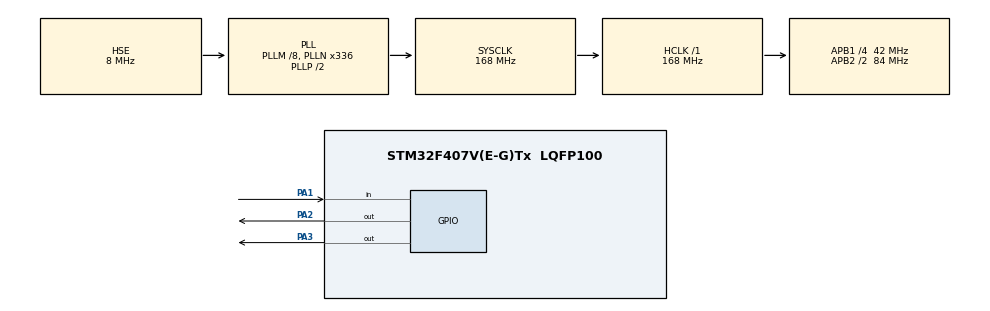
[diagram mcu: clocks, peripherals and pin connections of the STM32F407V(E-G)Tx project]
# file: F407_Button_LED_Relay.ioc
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Mcu.Family=STM32F4
Mcu.Name=STM32F407V(E-G)Tx
Mcu.Package=LQFP100
NVIC.PriorityGroup=NVIC_PRIORITYGROUP_4
PA1.GPIO_PuPd=GPIO_PULLUP
PA1.Signal=GPIO_Input
PA13.Mode=Trace_Asynchronous_SW
PA13.Signal=SYS_JTMS-SWDIO
PA14.Mode=Trace_Asynchronous_SW
PA14.Signal=SYS_JTCK-SWCLK
PA2.GPIO_ModeDefaultOutputPP=GPIO_MODE_OUTPUT_PP
PA2.GPIO_PuPd=GPIO_NOPULL
PA2.GPIO_Speed=GPIO_SPEED_FREQ_HIGH
PA2.PinState=GPIO_PIN_RESET
PA2.Signal=GPIO_Output
PA3.GPIO_ModeDefaultOutputPP=GPIO_MODE_OUTPUT_PP
PA3.GPIO_PuPd=GPIO_NOPULL
PA3.GPIO_Speed=GPIO_SPEED_FREQ_HIGH
PA3.PinState=GPIO_PIN_RESET
PA3.Signal=GPIO_Output
PB3.Mode=Trace_Asynchronous_SW
PB3.Signal=SYS_JTDO-SWO
PH0-OSC_IN.Mode=HSE-External-Oscillator
PH0-OSC_IN.Signal=RCC_OSC_IN
PH1-OSC_OUT.Mode=HSE-External-Oscillator
PH1-OSC_OUT.Signal=RCC_OSC_OUT
ProjectManager.HeapSize=0x200
ProjectManager.StackSize=0x400
ProjectManager.TargetToolchain=MDK-ARM V5.27
RCC.48MHZClocksFreq_Value=84000000
RCC.AHBFreq_Value=168000000
RCC.APB1CLKDivider=RCC_HCLK_DIV4
RCC.APB1Freq_Value=42000000
RCC.APB1TimFreq_Value=84000000
RCC.APB2CLKDivider=RCC_HCLK_DIV2
RCC.APB2Freq_Value=84000000
RCC.APB2TimFreq_Value=168000000
RCC.CortexFreq_Value=168000000
RCC.HCLKFreq_Value=168000000
RCC.HSE_VALUE=8000000
RCC.HSI_VALUE=16000000
RCC.LSE_VALUE=32768
RCC.PLLM=8
RCC.PLLN=336
RCC.PLLSourceVirtual=RCC_PLLSOURCE_HSE
RCC.SYSCLKFreq_VALUE=168000000
RCC.SYSCLKSource=RCC_SYSCLKSOURCE_PLLCLK
RCC.VCOOutputFreq_Value=336000000
board=custom

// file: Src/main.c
/* This code for STM32F407VG
Hardware setup:
PA1 -> GPIO_Input -> Pull up initialize,
    That means button is connected to GND,
		through RES10K to the PA0,1
PA2,3 -> GPIO_Output -> Output level (initial) low
			  								Mode - Output Push Pull
				  							No pull up/down
					  						Max. Output Speed - High
*/
#include "main.h"
#include "stdio.h"
void SystemClock_Config(void);
static void MX_GPIO_Init(void);
struct __FILE{
  int handle;
  /* Whatever you require here. If the only file you are using is */
  /* standard output using printf() for debugging, no file handling */
  /* is required. */
};
uint8_t count;
int main(void)
{
  HAL_Init();
  SystemClock_Config();
  MX_GPIO_Init();
  count = 0;
	while (1)
  {
		if(HAL_GPIO_ReadPin(GPIOA, GPIO_PIN_1) == 0)
		{
			count ++;
			if (count > 20)
				count = 0;
			HAL_Delay(200);																			//Bound effect avoidance
			while(HAL_GPIO_ReadPin(GPIOA, GPIO_PIN_1) == 0);		//Bound effect avoidance
			//HAL_Delay(200);																			//Bound effect avoidance
			HAL_GPIO_TogglePin(GPIOA, GPIO_PIN_2);
			HAL_GPIO_TogglePin(GPIOA, GPIO_PIN_3);
		}
  }
}

void SystemClock_Config(void)
{
  RCC_OscInitTypeDef RCC_OscInitStruct = {0};
  RCC_ClkInitTypeDef RCC_ClkInitStruct = {0};

  /** Configure the main internal regulator output voltage
  */
  __HAL_RCC_PWR_CLK_ENABLE();
  __HAL_PWR_VOLTAGESCALING_CONFIG(PWR_REGULATOR_VOLTAGE_SCALE1);
  /** Initializes the RCC Oscillators according to the specified parameters
  * in the RCC_OscInitTypeDef structure.
  */
  RCC_OscInitStruct.OscillatorType = RCC_OSCILLATORTYPE_HSE;
  RCC_OscInitStruct.HSEState = RCC_HSE_ON;
  RCC_OscInitStruct.PLL.PLLState = RCC_PLL_ON;
  RCC_OscInitStruct.PLL.PLLSource = RCC_PLLSOURCE_HSE;
  RCC_OscInitStruct.PLL.PLLM = 8;
  RCC_OscInitStruct.PLL.PLLN = 336;
  RCC_OscInitStruct.PLL.PLLP = RCC_PLLP_DIV2;
  RCC_OscInitStruct.PLL.PLLQ = 4;
  if (HAL_RCC_OscConfig(&RCC_OscInitStruct) != HAL_OK)
  {
    Error_Handler();
  }
  /** Initializes the CPU, AHB and APB buses clocks
  */
  RCC_ClkInitStruct.ClockType = RCC_CLOCKTYPE_HCLK|RCC_CLOCKTYPE_SYSCLK
                              |RCC_CLOCKTYPE_PCLK1|RCC_CLOCKTYPE_PCLK2;
  RCC_ClkInitStruct.SYSCLKSource = RCC_SYSCLKSOURCE_PLLCLK;
  RCC_ClkInitStruct.AHBCLKDivider = RCC_SYSCLK_DIV1;
  RCC_ClkInitStruct.APB1CLKDivider = RCC_HCLK_DIV4;
  RCC_ClkInitStruct.APB2CLKDivider = RCC_HCLK_DIV2;

  if (HAL_RCC_ClockConfig(&RCC_ClkInitStruct, FLASH_LATENCY_5) != HAL_OK)
  {
    Error_Handler();
  }
}

static void MX_GPIO_Init(void)
{
  GPIO_InitTypeDef GPIO_InitStruct = {0};

  /* GPIO Ports Clock Enable */
  __HAL_RCC_GPIOH_CLK_ENABLE();
  __HAL_RCC_GPIOA_CLK_ENABLE();
  __HAL_RCC_GPIOB_CLK_ENABLE();

  /*Configure GPIO pin Output Level */
  HAL_GPIO_WritePin(GPIOA, GPIO_PIN_2|GPIO_PIN_3, GPIO_PIN_RESET);

  /*Configure GPIO pin : PA1 */
  GPIO_InitStruct.Pin = GPIO_PIN_1;
  GPIO_InitStruct.Mode = GPIO_MODE_INPUT;
  GPIO_InitStruct.Pull = GPIO_PULLUP;
  HAL_GPIO_Init(GPIOA, &GPIO_InitStruct);

  /*Configure GPIO pins : PA2 PA3 */
  GPIO_InitStruct.Pin = GPIO_PIN_2|GPIO_PIN_3;
  GPIO_InitStruct.Mode = GPIO_MODE_OUTPUT_PP;
  GPIO_InitStruct.Pull = GPIO_NOPULL;
  GPIO_InitStruct.Speed = GPIO_SPEED_FREQ_HIGH;
  HAL_GPIO_Init(GPIOA, &GPIO_InitStruct);

}

/* USER CODE BEGIN 4 */
int fputc(int ch, FILE *f) {
    ITM_SendChar(ch);//send method for SWV
    return(ch);
}
/* USER CODE END 4 */

void Error_Handler(void)
{
}

/************************ (C) COPYRIGHT STMicroelectronics *****END OF FILE****/
